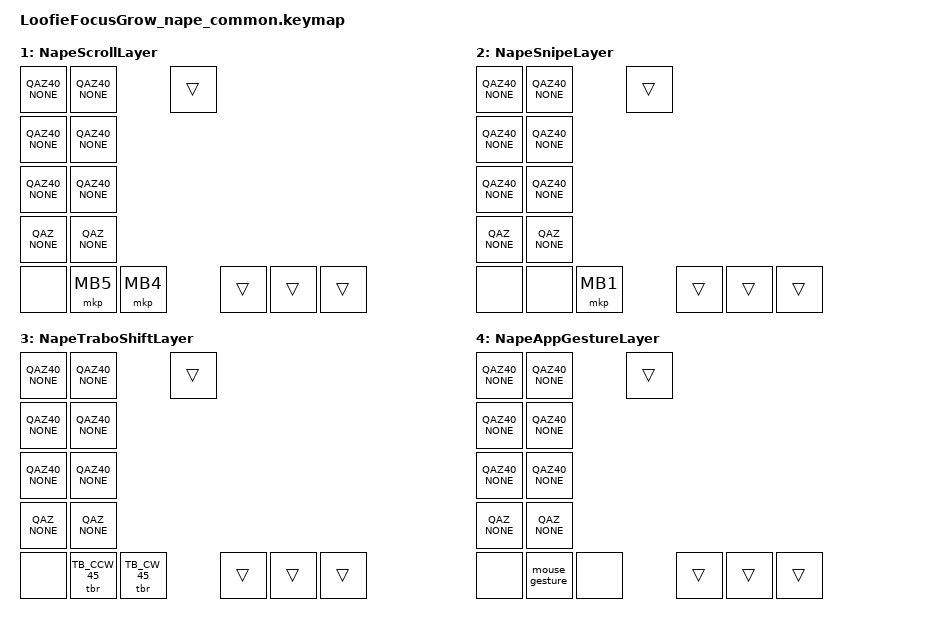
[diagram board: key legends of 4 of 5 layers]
#include <behaviors.dtsi>
#include <dt-bindings/zmk/keys.h>
#include <dt-bindings/zmk/bt.h>
#define ZMK_POINTING_DEFAULT_SCRL_VAL 30
#include <dt-bindings/zmk/pointing.h>
#include <input/processors.dtsi>
#include <behaviors/trackball_shift_rotation.dtsi>
#include <behaviors/trackball_direction_detection.dtsi>
#include <mouse-gesture.dtsi>
#include "us_keymap.h"

//╭──────┬────┬────┬────┬────┬────╮           ╭────┬────┬────┬────┬────┬────┬──────╮
//|  0   |  1 |  2 |  3 |  4 |  5 |           |  6 |  7 |  8 |  9 | 10 | 12 |  24  |
//├──────┴┬───┴┬───┴┬───┴┬───┴┬───┴╮          ╰┬───┴┬───┴┬───┴┬───┴┬───┴┬───┴╮     |
//|   13  | 14 | 15 | 16 | 17 | 18 |           | 19 | 20 | 21 | 22 | 23 | 11 |     |
//├───────┴──┬─┴──┬─┴──┬─┴──┬─┴──┬─┴──╮        ╰──┬─┴──┬─┴──┬─┴──┬─┴──┬─┴──┬─┴─────┤
//|   25     | 26 | 27 | 28 | 29 | 30 |           | 31 | 32 | 33 | 34 | 35 |   36  |
//├─────┬────┴┬───┴─┬──┴─┬──┴────┴──┬─╯          ╭┴────┴───┬┴────┼────┴┬───┴─┬─────┤
//|  37 |  38 |  39 | 40 |    41    |            |   42    |  43 |  44 |  45 |  46 |
//╰─────┴─────┴─────┴────┴──────────╯            ╰─────────┴─────┴─────┴─────┴─────╯

// Nape Front
//╭────┬────┬────┬────╮
//| 47 | TB | 48 | 49 |
//╰────┴────┴────┴────╯
// Nape Back from 1
//╭────┬────┬────╮
//| 50 | 51 | 52 |
//╰────┴────┴────╯

#define LEFT_TOP      0  1  2  3  4  5
#define RIGHT_TOP     6  7  8  9 10 11
#define RIGHT_ISO     12
#define LEFT_MID      13 14 15 16 17 18
#define RIGHT_MID     19 20 21 22 23 24
#define LEFT_BOTTOM   25 26 27 28 29 30
#define RIGHT_BOTTOM  31 32 33 34 35 36
#define LEFT_THUMBS   37 38 39 40 41
#define RIGHT_THUMBS  42 43 44 45 46
#define LEFT_KEYS LEFT_TOP LEFT_MID LEFT_BOTTOM
#define RIGHT_KEYS RIGHT_TOP RIGHT_ISO RIGHT_MID RIGHT_BOTTOM
#define THUMBS LEFT_THUMBS RIGHT_THUMBS

// For Nape
// Layer 0-7 are used for normal keymap.
#define L_SCROLL      8
#define L_SNIPE       9
#define L_TB_SHIFT   10
#define L_GEST_APP   11

#define LEFT_SPACE   LC(LEFT)
#define RIGHT_SPACE  LC(RIGHT)
#define MISSION_CTRL LC(UP)
#define EXPOSE       LC(DOWN)
#define LEFT_TAB     LS(LC(TAB))
#define RIGHT_TAB    LC(TAB)

// macro with globe
#define APP_LIST   globe_macro LS(A)
#define MAX_WIN    globe_macro LC(F)

// not define because globe is ignored in these cases....
// #define USE_GLOBE_CTRL
#ifdef USE_GLOBE_CTRL
#define MV_LEFT_WIN   globe_macro LC(LEFT)
#define MV_RIGHT_WIN  globe_macro LC(RIGHT)
#define MV_UP_WIN     globe_macro LC(UP)
#define MV_DOWN_WIN   globe_macro LC(DOWN)
#else
// shortcut with BetterTouchTool
#define MV_LEFT_WIN   kp LS(LG(LEFT))
#define MV_RIGHT_WIN  kp LS(LG(RIGHT))
#define MV_UP_WIN     kp LS(LG(UP))
#define MV_DOWN_WIN   kp LS(LG(DOWN))
#endif

&zip_mouse_gesture {
    stroke-size = <100>; // default: 200
    enable-eager-mode;
    suppress-movement;

    ges_left_space {
        pattern = <GESTURE_LEFT>;
        bindings = <&kp LEFT_SPACE>;
    };

    ges_right_space {
        pattern = <GESTURE_RIGHT>;
        bindings = <&kp RIGHT_SPACE>;
    };

    ges_mission_ctrl {
        pattern = <GESTURE_UP>;
        bindings = <&kp MISSION_CTRL>;
    };

    ges_expose {
        pattern = <GESTURE_DOWN>;
        bindings = <&kp EXPOSE>;
    };
};

/ {
    input_processors {
        zip_wheel_scaler: zip_wheel_scaler {
            compatible = "zmk,input-processor-scaler";
            #input-processor-cells = <2>;
            type = <INPUT_EV_REL>;
            codes = <INPUT_REL_WHEEL>;
            track-remainders;
        };

        zip_hwheel_scaler: zip_hwheel_scaler {
            compatible = "zmk,input-processor-scaler";
            #input-processor-cells = <2>;
            type = <INPUT_EV_REL>;
            codes = <INPUT_REL_HWHEEL>;
            track-remainders;
        };

        zip_window_gesture: zip_window_gesture {
            compatible = "zmk,input-processor-mouse-gesture";
            #input-processor-cells = <0>;

            stroke-size = <100>; // default: 200
            enable-eager-mode;
            suppress-movement;

            ges_left_win {
                pattern = <GESTURE_LEFT>;
                bindings = <&MV_LEFT_WIN>;
            };

            ges_right_win {
                pattern = <GESTURE_RIGHT>;
                bindings = <&MV_RIGHT_WIN>;
            };

            ges_up_win {
                pattern = <GESTURE_UP>;
                bindings = <&MV_UP_WIN>;
            };

            ges_down_win {
                pattern = <GESTURE_DOWN>;
                bindings = <&MV_DOWN_WIN>;
            };
        };

        zip_app_gesture: zip_app_gesture {
            compatible = "zmk,input-processor-mouse-gesture";
            #input-processor-cells = <0>;

            stroke-size = <100>; // default: 200
            enable-eager-mode;
            always-active;
            suppress-movement;

            ges_bri_dn {
                pattern = <GESTURE_LEFT>;
                bindings = <&kp C_BRI_DN>;
            };

            ges_bri_up {
                pattern = <GESTURE_RIGHT>;
                bindings = <&kp C_BRI_UP>;
            };

            ges_zoom_in {
                pattern = <GESTURE_UP>;
                bindings = <&kp LG(PLUS)>;
            };

            ges_zoom_dn {
                pattern = <GESTURE_DOWN>;
                bindings = <&kp LG(MINUS)>;
            };
        };
    };
};


/ {
    behaviors {
        mtb: mt_balanced {
            compatible = "zmk,behavior-hold-tap";
            #binding-cells = <2>;
            flavor = "balanced";
            tapping-term-ms = <200>;
            quick-tap-ms = <180>;
            bindings = <&kp>, <&kp>;
        };

        hml: home_row_mod_left {
            compatible = "zmk,behavior-hold-tap";
            #binding-cells = <2>;
            flavor = "balanced";
            require-prior-idle-ms = <150>;
            tapping-term-ms = <400>;
            quick-tap-ms = <180>;
            bindings = <&kp>, <&kp>;
            hold-trigger-key-positions = <THUMBS RIGHT_KEYS>;
            hold-trigger-on-release;
        };

        hmr: home_row_mod_right {
            compatible = "zmk,behavior-hold-tap";
            #binding-cells = <2>;
            flavor = "balanced";
            require-prior-idle-ms = <150>;
            tapping-term-ms = <400>;
            quick-tap-ms = <180>;
            bindings = <&kp>, <&kp>;
            hold-trigger-key-positions = <THUMBS LEFT_KEYS>;
            hold-trigger-on-release;
        };

        ht_tp: hold_tap_tap_preferred {
            compatible = "zmk,behavior-hold-tap";
            #binding-cells = <2>;
            flavor = "tap-preferred";
            tapping-term-ms = <200>;
            quick-tap-ms = <0>;
            bindings = <&kp>, <&kp>;
        };

    };

    combos {
        compatible = "zmk,combos";
        combo_capsword {
            timeout-ms = <50>;
            key-positions = <25 36>;
            bindings = <&caps_word>;
        };

        combo_esc_scroll {
            bindings = <&lt L_SCROLL ESC>;
            key-positions = <48 49>;
            timeout-ms = <50>;
        };

        combo_center_win_snipe_layer {
            bindings = <&lt_globe_macro L_SNIPE LC(C)>;
            key-positions = <47 48>;
            timeout-ms = <50>;
        };

        combo_max_win {
            bindings = <&MAX_WIN>;
            key-positions = <47 48 49>;
            timeout-ms = <50>;
        };

        combo_app_list {
            bindings = <&lt_globe_macro L_GEST_APP LS(A)>;
            key-positions = <47 49>;
            timeout-ms = <50>;
        };
    };

    // for Nape
    behaviors {
        lt_td: lt_td {
            compatible = "zmk,behavior-hold-tap";
            bindings = <&mo>, <&kp>;
            hold-while-undecided;

            #binding-cells = <2>;
            tapping-term-ms = <60>;
        };

        lt_mkp: lt_mkp {
            compatible = "zmk,behavior-hold-tap";
            bindings = <&mo>, <&mkp>;
            hold-while-undecided;

            #binding-cells = <2>;
            tapping-term-ms = <60>;
        };

        it_mkp: interrupted_mkp {
            compatible = "zmk,behavior-hold-tap";
            bindings = <&mo>, <&mkp>;
            flavor = "tap-unless-interrupted";

            #binding-cells = <2>;
            tapping-term-ms = <200>;
        };

        mod_mkp: mod_mkp {
            compatible = "zmk,behavior-hold-tap";
            bindings = <&kp>, <&mkp>;

            #binding-cells = <2>;
            tapping-term-ms = <200>;
        };

        td_spc_scrl_lang_tbs: td_b1 {
            compatible = "zmk,behavior-tap-dance";
            bindings = <&lt_td L_SCROLL SPACE>, <&lt_lang_macro L_TB_SHIFT SPACE>;
            #binding-cells = <0>;
            tapping-term-ms = <240>;
        };

        td_mb2_mac_adjust_gest: td_b2_m {
            compatible = "zmk,behavior-tap-dance";
            bindings = <&lt_mkp MAC(ADJUST) MB2>, <&mouse_gesture>;
            #binding-cells = <0>;
            tapping-term-ms = <240>;
        };

        td_mb2_win_adjust_gest: td_b2_w {
            compatible = "zmk,behavior-tap-dance";
            bindings = <&lt_mkp WIN(ADJUST) MB2>, <&mouse_gesture>;
            #binding-cells = <0>;
            tapping-term-ms = <240>;
        };

        lt_globe_macro: lt_globe_macro {
            compatible = "zmk,behavior-hold-tap";
            bindings = <&mo>, <&globe_macro>;

            #binding-cells = <2>;
            tapping-term-ms = <200>;
        };

        lt_lang_macro: lt_lang_macro {
            compatible = "zmk,behavior-hold-tap";
            bindings = <&mo>, <&lang_macro>;

            #binding-cells = <2>;
            tapping-term-ms = <200>;
        };
    };

    macro {
        globe_macro: globe_macro {
            compatible = "zmk,behavior-macro-one-param";
            #binding-cells = <1>;
            bindings
                = <&macro_press   &kp GLOBE>
                , <&macro_param_1to1>
                , <&macro_tap     &kp MACRO_PLACEHOLDER>
                , <&macro_release &kp GLOBE>
                ;
        };

        lang_macro: lang_macro {
            compatible = "zmk,behavior-macro";
            #binding-cells = <0>;
            bindings
                = <&macro_press   &kp LCTRL>
                , <&macro_tap     &kp SPACE>
                , <&macro_release &kp LCTRL>
                ;
        };
    };

    keymap {
        compatible = "zmk,keymap";

#define LAYER(s) MAC_##s##_layer

        LAYER(base) {
            bindings = <
                MAC_QAZ40_BASE_LEFT_TOP                 MAC_QAZ40_BASE_RIGHT_TOP     &kp RET
                MAC_QAZ40_BASE_LEFT_MIDDLE              MAC_QAZ40_BASE_RIGHT_MIDDLE
                MAC_QAZ40_BASE_LEFT_BOTTOM              MAC_QAZ40_BASE_RIGHT_BOTTOM
                &tb_dd  &none  MAC_QAZ_BASE_LEFT_THUMBS  MAC_QAZ_BASE_RIGHT_THUMBS    &none  &none
                &td_spc_scrl_lang_tbs  &td_mb2_mac_adjust_gest  &it_mkp MAC(ADJUST) MB1  &none &none &none
            >;
        };

        LAYER(raise) {
            bindings = <
                MAC_QAZ40_RAISE_LEFT_TOP                 MAC_QAZ40_RAISE_RIGHT_TOP     &trans
                MAC_QAZ40_RAISE_LEFT_MIDDLE              MAC_QAZ40_RAISE_RIGHT_MIDDLE
                MAC_QAZ40_RAISE_LEFT_BOTTOM              MAC_QAZ40_RAISE_RIGHT_BOTTOM
                &none  &none  MAC_QAZ_RAISE_LEFT_THUMBS  MAC_QAZ_RAISE_RIGHT_THUMBS   &tbr TB_0_DEG  &tbr TB_270_DEG
                &trans &trans &trans                     &trans &trans &trans
            >;
        };

        LAYER(lower) {
            bindings = <
                MAC_QAZ40_LOWER_LEFT_TOP                 MAC_QAZ40_LOWER_RIGHT_TOP     &trans
                MAC_QAZ40_LOWER_LEFT_MIDDLE              MAC_QAZ40_LOWER_RIGHT_MIDDLE
                MAC_QAZ40_LOWER_LEFT_BOTTOM              MAC_QAZ40_LOWER_RIGHT_BOTTOM
                &tbr TB_CCW_45  &tbr TB_CW_45  MAC_QAZ_LOWER_LEFT_THUMBS  MAC_QAZ_LOWER_RIGHT_THUMBS    &none  &none
                &trans &trans &trans                     &trans &trans &trans
            >;
        };

        LAYER(adjust) {
            bindings = <
                MAC_QAZ40_ADJUST_LEFT_TOP                 MAC_QAZ40_ADJUST_RIGHT_TOP     &trans
                MAC_QAZ40_ADJUST_LEFT_MIDDLE              MAC_QAZ40_ADJUST_RIGHT_MIDDLE
                MAC_QAZ40_ADJUST_LEFT_BOTTOM              MAC_QAZ40_ADJUST_RIGHT_BOTTOM
                &none  &none  MAC_QAZ_ADJUST_LEFT_THUMBS  MAC_QAZ_ADJUST_RIGHT_THUMBS    &none  &bootloader
                &mouse_gesture  &kp RIGHT_TAB  &kp LEFT_TAB  &trans &trans &trans
            >;
        };

#undef LAYER
#define LAYER(s) WIN_##s##_layer

        LAYER(base) {
            bindings = <
                WIN_QAZ40_BASE_LEFT_TOP                 WIN_QAZ40_BASE_RIGHT_TOP     &trans
                WIN_QAZ40_BASE_LEFT_MIDDLE              WIN_QAZ40_BASE_RIGHT_MIDDLE
                WIN_QAZ40_BASE_LEFT_BOTTOM              WIN_QAZ40_BASE_RIGHT_BOTTOM
                &tb_dd  &none  WIN_QAZ_BASE_LEFT_THUMBS  WIN_QAZ_BASE_RIGHT_THUMBS    &none  &none
                &td_spc_scrl_lang_tbs  &td_mb2_win_adjust_gest  &it_mkp WIN(ADJUST) MB1  &none &none &none
            >;
        };

        LAYER(raise) {
            bindings = <
                WIN_QAZ40_RAISE_LEFT_TOP                 WIN_QAZ40_RAISE_RIGHT_TOP     &trans
                WIN_QAZ40_RAISE_LEFT_MIDDLE              WIN_QAZ40_RAISE_RIGHT_MIDDLE
                WIN_QAZ40_RAISE_LEFT_BOTTOM              WIN_QAZ40_RAISE_RIGHT_BOTTOM
                &none  &none  WIN_QAZ_RAISE_LEFT_THUMBS  WIN_QAZ_RAISE_RIGHT_THUMBS    &tbr TB_0_DEG  &tbr TB_270_DEG
                &trans &trans &trans                     &trans &trans &trans
            >;
        };

        LAYER(lower) {
            bindings = <
                WIN_QAZ40_LOWER_LEFT_TOP                 WIN_QAZ40_LOWER_RIGHT_TOP     &trans
                WIN_QAZ40_LOWER_LEFT_MIDDLE              WIN_QAZ40_LOWER_RIGHT_MIDDLE
                WIN_QAZ40_LOWER_LEFT_BOTTOM              WIN_QAZ40_LOWER_RIGHT_BOTTOM
                &tbr TB_CCW_45  &tbr TB_CW_45  WIN_QAZ_LOWER_LEFT_THUMBS  WIN_QAZ_LOWER_RIGHT_THUMBS    &none  &none
                &trans &trans &trans                     &trans &trans &trans
            >;
        };

        LAYER(adjust) {
            bindings = <
                WIN_QAZ40_ADJUST_LEFT_TOP                 WIN_QAZ40_ADJUST_RIGHT_TOP     &trans
                WIN_QAZ40_ADJUST_LEFT_MIDDLE              WIN_QAZ40_ADJUST_RIGHT_MIDDLE
                WIN_QAZ40_ADJUST_LEFT_BOTTOM              WIN_QAZ40_ADJUST_RIGHT_BOTTOM
                &none  &none  WIN_QAZ_ADJUST_LEFT_THUMBS  WIN_QAZ_ADJUST_RIGHT_THUMBS    &none  &none
                &mouse_gesture  &kp RIGHT_TAB  &kp LEFT_TAB  &trans &trans &trans
            >;
        };

        NapeScrollLayer {
            bindings = <
                QAZ40_NONE  QAZ40_NONE  &trans
                QAZ40_NONE  QAZ40_NONE
                QAZ40_NONE  QAZ40_NONE
                QAZ_NONE    QAZ_NONE
                &none  &mkp MB5  &mkp MB4                 &trans &trans &trans
            >;
        };

        NapeSnipeLayer {
            bindings = <
                QAZ40_NONE  QAZ40_NONE  &trans
                QAZ40_NONE  QAZ40_NONE
                QAZ40_NONE  QAZ40_NONE
                QAZ_NONE    QAZ_NONE
                &none     &none     &mkp MB1  &trans &trans &trans
            >;
        };

        NapeTraboShiftLayer {
            bindings = <
                QAZ40_NONE  QAZ40_NONE  &trans
                QAZ40_NONE  QAZ40_NONE
                QAZ40_NONE  QAZ40_NONE
                QAZ_NONE    QAZ_NONE
                &none  &tbr TB_CCW_45  &tbr TB_CW_45  &trans &trans &trans
            >;
        };

        NapeAppGestureLayer {
            bindings = <
                QAZ40_NONE  QAZ40_NONE  &trans
                QAZ40_NONE  QAZ40_NONE
                QAZ40_NONE  QAZ40_NONE
                QAZ_NONE    QAZ_NONE
                &none  &mouse_gesture  &none  &trans &trans &trans
            >;
        };
    };
};
